# nrf9120_mlm1 register map
Vendor: Nordic Semiconductor; Series: nrf91; File version: 1
CPU: CM4 r0p1, little endian, MPU, FPU, 3 interrupt priority bits
Registers are 32-bit, read-write, reset 0x0 unless marked. A register's access mark holds for its fields unless they carry their own. Offsets are from the block's base; [hi:lo] are bit positions; lines under a group give offsets from that group; {n}, {i} and the like mark numbered series; 'fields as' and 'values as' point back to an identical list.

## MWU — Memory Watch Unit
Base 0x40001000
{0x100+8i} EVENTS_REGION[{i}] (i=0..3) group — Peripheral events.
  0x00 WA — Description cluster: Write access to region n detected
    [0] WA — Write access to region n detected
      0=NotGenerated (Event not generated); 1=Generated (Event generated)
  0x04 RA — Description cluster: Read access to region n detected
    [0] RA — Read access to region n detected
      values as EVENTS_REGION[0].WA.WA
{0x160+8i} EVENTS_PREGION[{i}] (i=0..1) group — Peripheral events.
  0x00 WA — Description cluster: Write access to peripheral region n detected
    [0] WA — Write access to peripheral region n detected
      values as EVENTS_REGION[0].WA.WA
  0x04 RA — Description cluster: Read access to peripheral region n detected
    [0] RA — Read access to peripheral region n detected
      values as EVENTS_REGION[0].WA.WA
{0x180+8i} PUBLISH_REGION[{i}] (i=0..3) group — Publish configuration for events
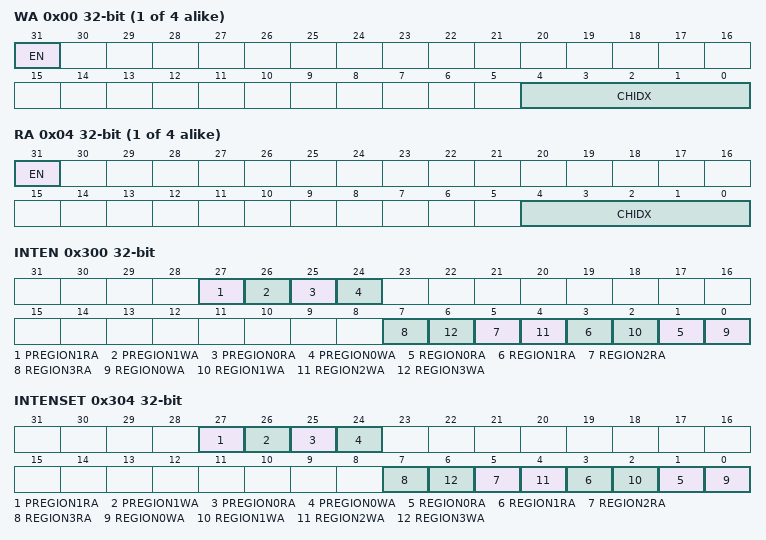
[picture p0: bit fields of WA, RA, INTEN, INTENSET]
  0x00 WA — Description cluster: Publish configuration for event REGION[n].WA
    [31] EN
      0=Disabled (Disable publishing); 1=Enabled (Enable publishing)
    [4:0] CHIDX — Channel that event REGION[n].WA will publish to.
  0x04 RA — Description cluster: Publish configuration for event REGION[n].RA
    [31] EN
      values as PUBLISH_REGION[0].WA.EN
    [4:0] CHIDX — Channel that event REGION[n].RA will publish to.
{0x1E0+8i} PUBLISH_PREGION[{i}] (i=0..1) group — Publish configuration for events
  0x00 WA — Description cluster: Publish configuration for event PREGION[n].WA
    [31] EN
      values as PUBLISH_REGION[0].WA.EN
    [4:0] CHIDX — Channel that event PREGION[n].WA will publish to.
  0x04 RA — Description cluster: Publish configuration for event PREGION[n].RA
    [31] EN
      values as PUBLISH_REGION[0].WA.EN
    [4:0] CHIDX — Channel that event PREGION[n].RA will publish to.
0x300 INTEN — Enable or disable interrupt
  [all] fields
    0=Disabled; 1=Enabled
  [27] PREGION1RA — Enable or disable interrupt for event PREGION1RA
  [26] PREGION1WA — Enable or disable interrupt for event PREGION1WA
  [25] PREGION0RA — Enable or disable interrupt for event PREGION0RA
  [24] PREGION0WA — Enable or disable interrupt for event PREGION0WA
  [2n+1] REGION{n}RA (n=0..3) — Enable or disable interrupt for event REGION{n}RA
  [2n] REGION{n}WA (n=0..3) — Enable or disable interrupt for event REGION{n}WA
0x304 INTENSET — Enable interrupt
  [all] fields
    on read: 0=Disabled (Read: Disabled); 1=Enabled (Read: Enabled) | on write: 1=Set (Enable)
  [27] PREGION1RA — Write '1' to enable interrupt for event PREGION1RA
  [26] PREGION1WA — Write '1' to enable interrupt for event PREGION1WA
  [25] PREGION0RA — Write '1' to enable interrupt for event PREGION0RA
  [24] PREGION0WA — Write '1' to enable interrupt for event PREGION0WA
  [2n+1] REGION{n}RA (n=0..3) — Write '1' to enable interrupt for event REGION{n}RA
  [2n] REGION{n}WA (n=0..3) — Write '1' to enable interrupt for event REGION{n}WA
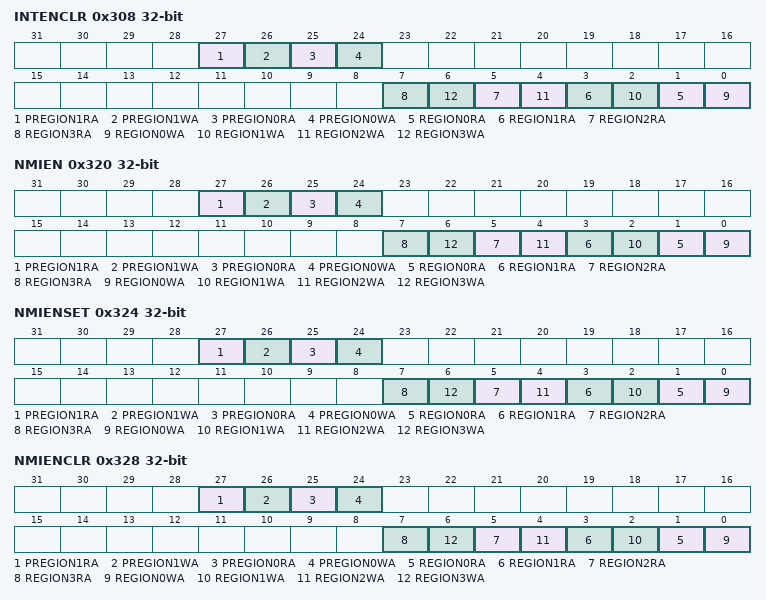
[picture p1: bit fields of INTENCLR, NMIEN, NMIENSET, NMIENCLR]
0x308 INTENCLR — Disable interrupt
  [all] fields
    on read: 0=Disabled (Read: Disabled); 1=Enabled (Read: Enabled) | on write: 1=Clear (Disable)
  [27] PREGION1RA — Write '1' to disable interrupt for event PREGION1RA
  [26] PREGION1WA — Write '1' to disable interrupt for event PREGION1WA
  [25] PREGION0RA — Write '1' to disable interrupt for event PREGION0RA
  [24] PREGION0WA — Write '1' to disable interrupt for event PREGION0WA
  [2n+1] REGION{n}RA (n=0..3) — Write '1' to disable interrupt for event REGION{n}RA
  [2n] REGION{n}WA (n=0..3) — Write '1' to disable interrupt for event REGION{n}WA
0x320 NMIEN — Enable or disable interrupt
  fields as INTEN
0x324 NMIENSET — Enable interrupt
  fields as INTENSET
0x328 NMIENCLR — Disable interrupt
  fields as INTENCLR
{0x400+8i} PERREGION[{i}] (i=0..1) group — Unspecified
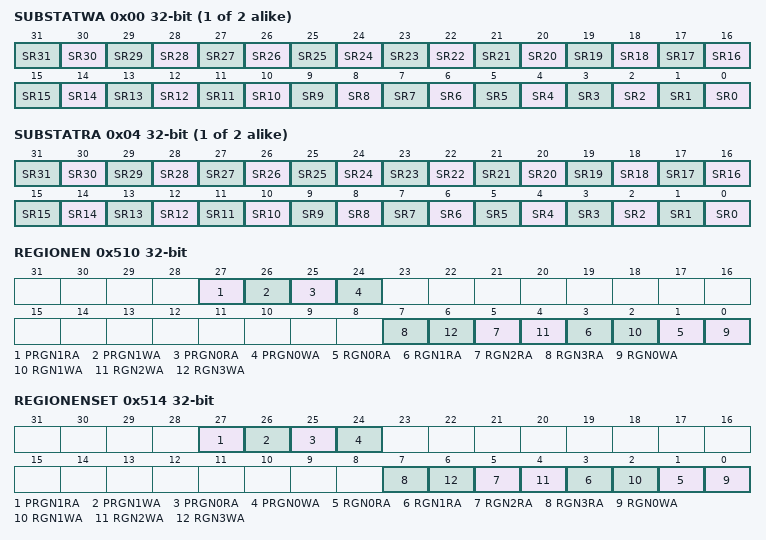
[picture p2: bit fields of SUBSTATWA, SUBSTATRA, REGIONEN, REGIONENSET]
  0x00 SUBSTATWA write-1-clears — Description cluster: Source of event/interrupt in region n, write access detected while corresponding subregion was enabled for watching
    [all] fields
      0=NoAccess (No write access occurred in this subregion); 1=Access (Write access(es) occurred in this subregion)
    [n] SR{n} (n=0..31) — Subregion {n} in region n (write '1' to clear)
  0x04 SUBSTATRA write-1-clears — Description cluster: Source of event/interrupt in region n, read access detected while corresponding subregion was enabled for watching
    [all] fields
      0=NoAccess (No read access occurred in this subregion); 1=Access (Read access(es) occurred in this subregion)
    [n] SR{n} (n=0..31) — Subregion {n} in region n (write '1' to clear)
0x510 REGIONEN — Enable/disable regions watch
  [27] PRGN1RA — Enable/disable read access watch in PREGION[1]
    0=Disable read access watch in this PREGION; 1=Enable read access watch in this PREGION
  [26] PRGN1WA — Enable/disable write access watch in PREGION[1]
    0=Disable write access watch in this PREGION; 1=Enable write access watch in this PREGION
  [25] PRGN0RA — Enable/disable read access watch in PREGION[0]
    values as PRGN1RA
  [24] PRGN0WA — Enable/disable write access watch in PREGION[0]
    values as PRGN1WA
  [2n+1] RGN{n}RA (n=0..3) — Enable/disable read access watch in region[{n}]
    0=Disable read access watch in this region; 1=Enable read access watch in this region
  [2n] RGN{n}WA (n=0..3) — Enable/disable write access watch in region[{n}]
    0=Disable write access watch in this region; 1=Enable write access watch in this region
0x514 REGIONENSET — Enable regions watch
  [27] PRGN1RA — Enable read access watch in PREGION[1]
    on read: 0=Disabled (Read access watch in this PREGION is disabled); 1=Enabled (Read access watch in this PREGION is enabled) | on write: 1=Set (Enable read access watch in this PREGION)
  [26] PRGN1WA — Enable write access watch in PREGION[1]
    on read: 0=Disabled (Write access watch in this PREGION is disabled); 1=Enabled (Write access watch in this PREGION is enabled) | on write: 1=Set (Enable write access watch in this PREGION)
  [25] PRGN0RA — Enable read access watch in PREGION[0]
    values as PRGN1RA
  [24] PRGN0WA — Enable write access watch in PREGION[0]
    values as PRGN1WA
  [2n+1] RGN{n}RA (n=0..3) — Enable read access watch in region[{n}]
    on read: 0=Disabled (Read access watch in this region is disabled); 1=Enabled (Read access watch in this region is enabled) | on write: 1=Set (Enable read access watch in this region)
  [2n] RGN{n}WA (n=0..3) — Enable write access watch in region[{n}]
    on read: 0=Disabled (Write access watch in this region is disabled); 1=Enabled (Write access watch in this region is enabled) | on write: 1=Set (Enable write access watch in this region)
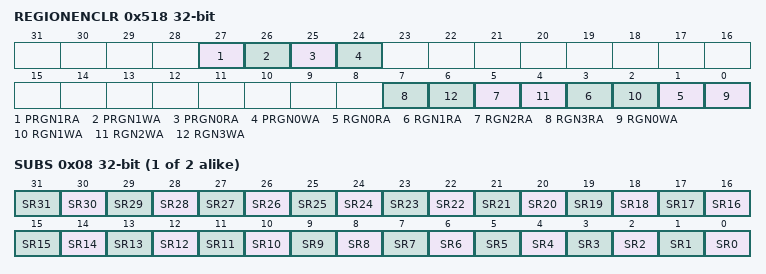
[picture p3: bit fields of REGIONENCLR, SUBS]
0x518 REGIONENCLR — Disable regions watch
  [27] PRGN1RA — Disable read access watch in PREGION[1]
    on read: 0=Disabled (Read access watch in this PREGION is disabled); 1=Enabled (Read access watch in this PREGION is enabled) | on write: 1=Clear (Disable read access watch in this PREGION)
  [26] PRGN1WA — Disable write access watch in PREGION[1]
    on read: 0=Disabled (Write access watch in this PREGION is disabled); 1=Enabled (Write access watch in this PREGION is enabled) | on write: 1=Clear (Disable write access watch in this PREGION)
  [25] PRGN0RA — Disable read access watch in PREGION[0]
    values as PRGN1RA
  [24] PRGN0WA — Disable write access watch in PREGION[0]
    values as PRGN1WA
  [2n+1] RGN{n}RA (n=0..3) — Disable read access watch in region[{n}]
    on read: 0=Disabled (Read access watch in this region is disabled); 1=Enabled (Read access watch in this region is enabled) | on write: 1=Clear (Disable read access watch in this region)
  [2n] RGN{n}WA (n=0..3) — Disable write access watch in region[{n}]
    on read: 0=Disabled (Write access watch in this region is disabled); 1=Enabled (Write access watch in this region is enabled) | on write: 1=Clear (Disable write access watch in this region)
{0x600+0x10*i} REGION[{i}] (i=0..3) group — Unspecified
  0x00 START — Description cluster: Start address for region n
    [31:0] START — Start address for region
  0x04 END — Description cluster: End address of region n
    [31:0] END — End address of region.
{0x6C0+0x10*i} PREGION[{i}] (i=0..1) group — Unspecified
  0x00 START ro — Description cluster: Reserved for future use
    [31:0] START — Reserved for future use
  0x04 END ro — Description cluster: Reserved for future use
    [31:0] END — Reserved for future use
  0x08 SUBS — Description cluster: Subregions of region n
    [all] fields
      0=Exclude; 1=Include
    [n] SR{n} (n=0..31) — Include or exclude subregion {n} in region
